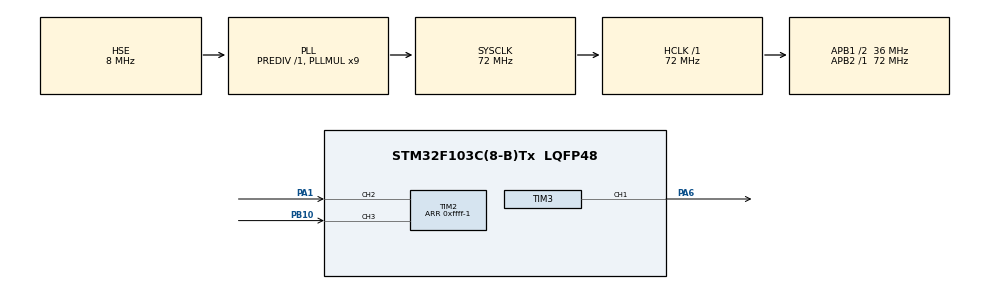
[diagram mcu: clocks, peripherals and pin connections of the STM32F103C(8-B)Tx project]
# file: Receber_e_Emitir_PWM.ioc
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Mcu.Family=STM32F1
Mcu.Name=STM32F103C(8-B)Tx
Mcu.Package=LQFP48
NVIC.PriorityGroup=NVIC_PRIORITYGROUP_4
PA1.Signal=S_TIM2_CH2
PA13.Mode=Serial_Wire
PA13.Signal=SYS_JTMS-SWDIO
PA14.Mode=Serial_Wire
PA14.Signal=SYS_JTCK-SWCLK
PA6.Signal=S_TIM3_CH1
PB10.Signal=S_TIM2_CH3
PD0-OSC_IN.Mode=HSE-External-Oscillator
PD0-OSC_IN.Signal=RCC_OSC_IN
PD1-OSC_OUT.Mode=HSE-External-Oscillator
PD1-OSC_OUT.Signal=RCC_OSC_OUT
ProjectManager.HeapSize=0x200
ProjectManager.StackSize=0x400
ProjectManager.TargetToolchain=STM32CubeIDE
RCC.AHBFreq_Value=72000000
RCC.APB1CLKDivider=RCC_HCLK_DIV2
RCC.APB1Freq_Value=36000000
RCC.APB1TimFreq_Value=72000000
RCC.APB2Freq_Value=72000000
RCC.APB2TimFreq_Value=72000000
RCC.HCLKFreq_Value=72000000
RCC.PLLMUL=RCC_PLL_MUL9
RCC.PLLSourceVirtual=RCC_PLLSOURCE_HSE
RCC.SYSCLKFreq_VALUE=72000000
RCC.SYSCLKSource=RCC_SYSCLKSOURCE_PLLCLK
RCC.USBFreq_Value=72000000
SH.S_TIM2_CH2.0=TIM2_CH2,Input_Capture2_from_TI2
SH.S_TIM2_CH2.1=TIM2_CH2,TriggerSource_TI2FP2
SH.S_TIM2_CH3.0=TIM2_CH3,Input_Capture3_from_TI3
SH.S_TIM3_CH1.0=TIM3_CH1,PWM Generation1 CH1
TIM2.Channel-Input_Capture2_from_TI2=TIM_CHANNEL_2
TIM2.Channel-Input_Capture3_from_TI3=TIM_CHANNEL_3
TIM2.ICPolarity_CH3=TIM_INPUTCHANNELPOLARITY_FALLING
TIM2.Period=0xffff-1
TIM3.Channel-PWM\ Generation1\ CH1=TIM_CHANNEL_1
TIM3.Period=1000
TIM3.Prescaler=32000
TIM3.Pulse-PWM\ Generation1\ CH1=500
VP_TIM2_VS_ControllerModeReset.Mode=Reset Mode
VP_TIM3_VS_ClockSourceINT.Mode=Internal
board=custom

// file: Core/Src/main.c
/* USER CODE BEGIN Header */
/**
  ******************************************************************************
  * @file           : main.c
  * @brief          : Main program body
  ******************************************************************************
  * @attention
  *
  * <h2><center>&copy; Copyright (c) 2020 STMicroelectronics.
  * All rights reserved.</center></h2>
  *
  * This software component is licensed by ST under BSD 3-Clause license,
  * the "License"; You may not use this file except in compliance with the
  * License. You may obtain a copy of the License at:
  *                        opensource.org/licenses/BSD-3-Clause
  *
  ******************************************************************************
  */
/* USER CODE END Header */

#include "main.h"

TIM_HandleTypeDef htim2;
TIM_HandleTypeDef htim3;

void SystemClock_Config(void);
static void MX_GPIO_Init(void);
static void MX_TIM2_Init(void);
static void MX_TIM3_Init(void);

/* USER CODE BEGIN 0 */

//1.
uint32_t IC_Val1 = 0;
uint32_t IC_Val2 = 0;
uint32_t Frequency = 0;
uint32_t Duty_Cycle = 0;

//2.

void HAL_TIM_IC_CaptureCallback( TIM_HandLeTypeDef *htim)
{
	if(htim->Channel == HAL_TIM_ACTIVATE_CHANNEL_2) //rising edge interrupt
	{
		//read capture value
		IC_Val1 = HAL_TIMReadCaptureValue(htim, TIM_CHANNEL_2); // first value

		if (IC_Val1 != 0) //
		{
			//read the second value
			IC_Val2 = HAL_TIMReadCaptureValue(htim, TIM_CHANNEL_3); //falling edge value

			Duty_Cycle = (IC_Val2*100/IC_Val1);

			Frequency = (2*HAL_RCC_GetPCLK1Freq()/IC_Val1); //timer 2 clock é 2x PCLK1 CLOCK
		}
		else
		{
			Duty_Cycle = 0;
			Frequency = 0;

		}
	}

}

/* USER CODE END 0 */

int main(void)
{

  /* MCU Configuration--------------------------------------------------------*/

  /* Reset of all peripherals, Initializes the Flash interface and the Systick. */
  HAL_Init();

  /* Configure the system clock */
  SystemClock_Config();

  /* Initialize all configured peripherals */
  MX_GPIO_Init();
  MX_TIM2_Init();
  MX_TIM3_Init();
  /* USER CODE BEGIN 2 */
  HAL_TIM_PWM_Start(&htim3, TIM_CHANNEL_1);
  HAL_TIM_IC_Start_IT (&htim, TIM_CHANNEL_2);
  HAL_TIM_IC_Start_IT (&htim, TIM_CHANNEL_3);

  /* USER CODE END 2 */

  /* Infinite loop */
  while (1)
  {

  }
}

void SystemClock_Config(void)
{
  RCC_OscInitTypeDef RCC_OscInitStruct = {0};
  RCC_ClkInitTypeDef RCC_ClkInitStruct = {0};

  /** Initializes the CPU, AHB and APB busses clocks
  */
  RCC_OscInitStruct.OscillatorType = RCC_OSCILLATORTYPE_HSE;
  RCC_OscInitStruct.HSEState = RCC_HSE_ON;
  RCC_OscInitStruct.HSEPredivValue = RCC_HSE_PREDIV_DIV1;
  RCC_OscInitStruct.HSIState = RCC_HSI_ON;
  RCC_OscInitStruct.PLL.PLLState = RCC_PLL_ON;
  RCC_OscInitStruct.PLL.PLLSource = RCC_PLLSOURCE_HSE;
  RCC_OscInitStruct.PLL.PLLMUL = RCC_PLL_MUL9;
  if (HAL_RCC_OscConfig(&RCC_OscInitStruct) != HAL_OK)
  {
    Error_Handler();
  }
  /** Initializes the CPU, AHB and APB busses clocks
  */
  RCC_ClkInitStruct.ClockType = RCC_CLOCKTYPE_HCLK|RCC_CLOCKTYPE_SYSCLK
                              |RCC_CLOCKTYPE_PCLK1|RCC_CLOCKTYPE_PCLK2;
  RCC_ClkInitStruct.SYSCLKSource = RCC_SYSCLKSOURCE_PLLCLK;
  RCC_ClkInitStruct.AHBCLKDivider = RCC_SYSCLK_DIV1;
  RCC_ClkInitStruct.APB1CLKDivider = RCC_HCLK_DIV2;
  RCC_ClkInitStruct.APB2CLKDivider = RCC_HCLK_DIV1;

  if (HAL_RCC_ClockConfig(&RCC_ClkInitStruct, FLASH_LATENCY_2) != HAL_OK)
  {
    Error_Handler();
  }
}

static void MX_TIM2_Init(void)
{

  TIM_SlaveConfigTypeDef sSlaveConfig = {0};
  TIM_MasterConfigTypeDef sMasterConfig = {0};
  TIM_IC_InitTypeDef sConfigIC = {0};

  htim2.Instance = TIM2;
  htim2.Init.Prescaler = 0;
  htim2.Init.CounterMode = TIM_COUNTERMODE_UP;
  htim2.Init.Period = 0xffff-1;
  htim2.Init.ClockDivision = TIM_CLOCKDIVISION_DIV1;
  htim2.Init.AutoReloadPreload = TIM_AUTORELOAD_PRELOAD_DISABLE;
  if (HAL_TIM_Base_Init(&htim2) != HAL_OK)
  {
    Error_Handler();
  }
  if (HAL_TIM_IC_Init(&htim2) != HAL_OK)
  {
    Error_Handler();
  }
  sSlaveConfig.SlaveMode = TIM_SLAVEMODE_RESET;
  sSlaveConfig.InputTrigger = TIM_TS_TI2FP2;
  sSlaveConfig.TriggerPolarity = TIM_INPUTCHANNELPOLARITY_RISING;
  sSlaveConfig.TriggerFilter = 0;
  if (HAL_TIM_SlaveConfigSynchro(&htim2, &sSlaveConfig) != HAL_OK)
  {
    Error_Handler();
  }
  sMasterConfig.MasterOutputTrigger = TIM_TRGO_RESET;
  sMasterConfig.MasterSlaveMode = TIM_MASTERSLAVEMODE_DISABLE;
  if (HAL_TIMEx_MasterConfigSynchronization(&htim2, &sMasterConfig) != HAL_OK)
  {
    Error_Handler();
  }
  sConfigIC.ICPolarity = TIM_INPUTCHANNELPOLARITY_RISING;
  sConfigIC.ICSelection = TIM_ICSELECTION_DIRECTTI;
  sConfigIC.ICPrescaler = TIM_ICPSC_DIV1;
  sConfigIC.ICFilter = 0;
  if (HAL_TIM_IC_ConfigChannel(&htim2, &sConfigIC, TIM_CHANNEL_2) != HAL_OK)
  {
    Error_Handler();
  }
  sConfigIC.ICPolarity = TIM_INPUTCHANNELPOLARITY_FALLING;
  if (HAL_TIM_IC_ConfigChannel(&htim2, &sConfigIC, TIM_CHANNEL_3) != HAL_OK)
  {
    Error_Handler();
  }

}

static void MX_TIM3_Init(void)
{

  TIM_ClockConfigTypeDef sClockSourceConfig = {0};
  TIM_MasterConfigTypeDef sMasterConfig = {0};
  TIM_OC_InitTypeDef sConfigOC = {0};

  htim3.Instance = TIM3;
  htim3.Init.Prescaler = 32000;
  htim3.Init.CounterMode = TIM_COUNTERMODE_UP;
  htim3.Init.Period = 1000;
  htim3.Init.ClockDivision = TIM_CLOCKDIVISION_DIV1;
  htim3.Init.AutoReloadPreload = TIM_AUTORELOAD_PRELOAD_DISABLE;
  if (HAL_TIM_Base_Init(&htim3) != HAL_OK)
  {
    Error_Handler();
  }
  sClockSourceConfig.ClockSource = TIM_CLOCKSOURCE_INTERNAL;
  if (HAL_TIM_ConfigClockSource(&htim3, &sClockSourceConfig) != HAL_OK)
  {
    Error_Handler();
  }
  if (HAL_TIM_PWM_Init(&htim3) != HAL_OK)
  {
    Error_Handler();
  }
  sMasterConfig.MasterOutputTrigger = TIM_TRGO_RESET;
  sMasterConfig.MasterSlaveMode = TIM_MASTERSLAVEMODE_DISABLE;
  if (HAL_TIMEx_MasterConfigSynchronization(&htim3, &sMasterConfig) != HAL_OK)
  {
    Error_Handler();
  }
  sConfigOC.OCMode = TIM_OCMODE_PWM1;
  sConfigOC.Pulse = 500;
  sConfigOC.OCPolarity = TIM_OCPOLARITY_HIGH;
  sConfigOC.OCFastMode = TIM_OCFAST_DISABLE;
  if (HAL_TIM_PWM_ConfigChannel(&htim3, &sConfigOC, TIM_CHANNEL_1) != HAL_OK)
  {
    Error_Handler();
  }
  HAL_TIM_MspPostInit(&htim3);

}

static void MX_GPIO_Init(void)
{

  /* GPIO Ports Clock Enable */
  __HAL_RCC_GPIOD_CLK_ENABLE();
  __HAL_RCC_GPIOA_CLK_ENABLE();
  __HAL_RCC_GPIOB_CLK_ENABLE();

}

void Error_Handler(void)
{
}

/************************ (C) COPYRIGHT STMicroelectronics *****END OF FILE****/
